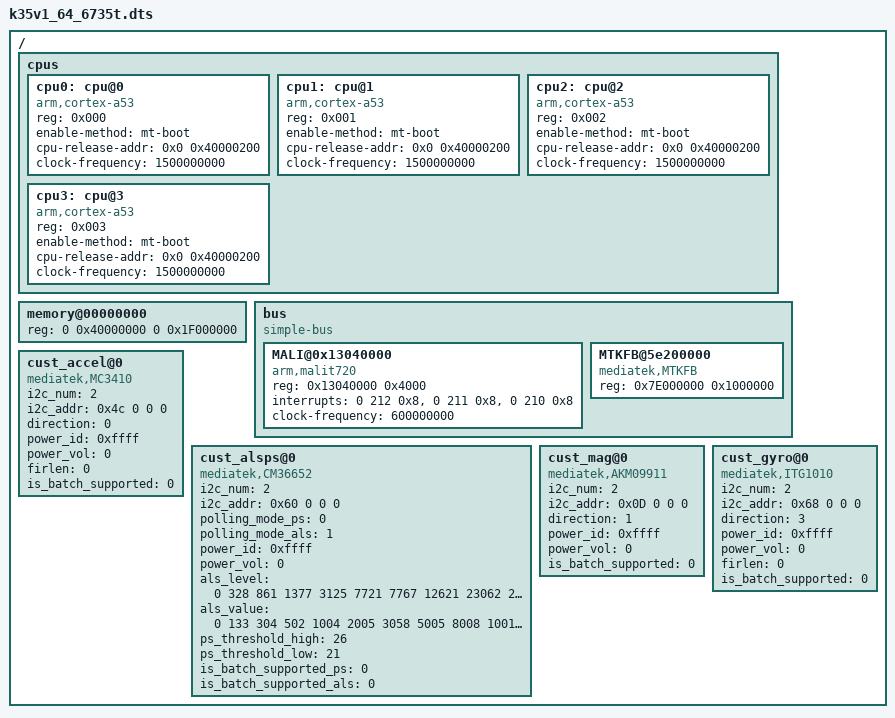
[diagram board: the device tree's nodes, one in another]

/dts-v1/;

#include "mt6735.dtsi"

/ {
	cpus {	#address-cells = <1>;
		#size-cells = <0>;

		cpu0: cpu@0 {
			device_type = "cpu";
			compatible = "arm,cortex-a53";
			reg = <0x000>;
			enable-method = "mt-boot";
			cpu-release-addr = <0x0 0x40000200>;
			clock-frequency = <1500000000>;
		};

		cpu1: cpu@1 {
			device_type = "cpu";
			compatible = "arm,cortex-a53";
			reg = <0x001>;
			enable-method = "mt-boot";
			cpu-release-addr = <0x0 0x40000200>;
			clock-frequency = <1500000000>;
		};

		cpu2: cpu@2 {
			device_type = "cpu";
			compatible = "arm,cortex-a53";
			reg = <0x002>;
			enable-method = "mt-boot";
			cpu-release-addr = <0x0 0x40000200>;
			clock-frequency = <1500000000>;
		};

		cpu3: cpu@3 {
			device_type = "cpu";
			compatible = "arm,cortex-a53";
			reg = <0x003>;
			enable-method = "mt-boot";
			cpu-release-addr = <0x0 0x40000200>;
			clock-frequency = <1500000000>;
		};
	};

  memory@00000000 {
		device_type = "memory";
		reg = <0 0x40000000 0 0x1F000000>;
	};

	bus {
		compatible = "simple-bus";
		#address-cells = <1>;
		#size-cells = <1>;
		ranges = <0 0 0 0xffffffff>;

		MALI@0x13040000 {
			compatible = "arm,malit720", "arm,mali-t72x", "arm,malit7xx", "arm,mali-midgard";
			reg = <0x13040000 0x4000>;
			interrupts = <0 212 0x8>, <0 211 0x8>, <0 210 0x8>;
			interrupt-names = "JOB", "MMU", "GPU";
			clock-frequency = <600000000>;
		};

		MTKFB@5e200000 {
			compatible = "mediatek,MTKFB";
			reg = <0x7E000000 0x1000000>;
		};

  };
  /*  start sensor */
		cust_accel@0 {
		compatible 				= "mediatek,MC3410";
		i2c_num 				= <2>;
		i2c_addr				= <0x4c 0 0 0>;
		direction 				= <0>;
		power_id 				= <0xffff>;
		power_vol				= <0>;
		firlen 					= <0>;
		is_batch_supported  			= <0>;
  		};
  
		cust_alsps@0 {
		compatible 				= "mediatek,CM36652";
		i2c_num 				= <2>;
		i2c_addr 				= <0x60 0 0 0>;
		polling_mode_ps			= <0>;
		polling_mode_als		= <1>;
		power_id   				= <0xffff>;
		power_vol  				= <0>; 
/* Total has 15 level*/
		als_level  				= <0 328 861 1377 3125 7721 7767 12621 23062 28430 33274 47116 57694 57694 65535>;
/*  Total has 16 range*/
		als_value  				= <0 133 304 502 1004 2005 3058 5005 8008 10010 12000 16000 20000 20000 20000 20000>;
		ps_threshold_high		=  <26>;
		ps_threshold_low		=  <21>;
		is_batch_supported_ps	= <0>;
		is_batch_supported_als	= <0>;
		};
		
  		cust_mag@0 {
		compatible				= "mediatek,AKM09911";
		i2c_num 				= <2>;
		i2c_addr				= <0x0D 0 0 0>;
		direction 				= <1>;
		power_id 				= <0xffff>;
		power_vol				= <0>;
		is_batch_supported  	= <0>;
  		};
		
  		cust_gyro@0 {
		compatible 				= "mediatek,ITG1010";
		i2c_num 				= <2>;
		i2c_addr				= <0x68 0 0 0>;
		direction 				= <3>;
		power_id 				= <0xffff>;
		power_vol				= <0>;
		firlen 					= <0>;
		is_batch_supported  	= <0>;
  		};
  /* end sensor */
};
